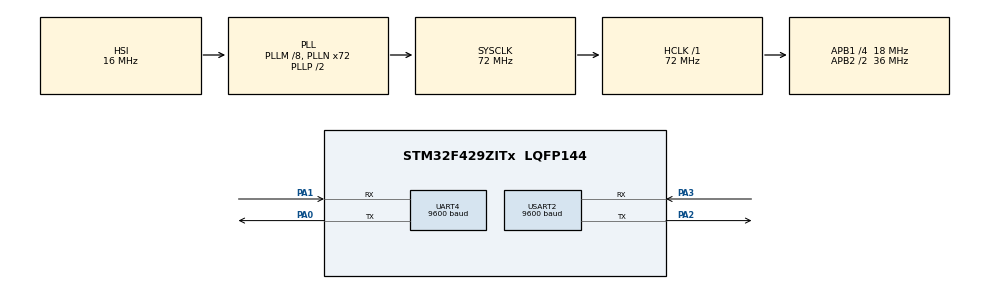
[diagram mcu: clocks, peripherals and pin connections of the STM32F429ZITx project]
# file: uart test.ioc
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Mcu.Family=STM32F4
Mcu.Name=STM32F429ZITx
Mcu.Package=LQFP144
Mcu.UserConstants=out,1
NVIC.PriorityGroup=NVIC_PRIORITYGROUP_4
NVIC.TIM1_UP_TIM10_IRQn=true\:0\:0\:false\:false\:true\:false\:true
NVIC.TimeBase=TIM1_UP_TIM10_IRQn
NVIC.TimeBaseIP=TIM1
NVIC.UART4_IRQn=true\:0\:0\:false\:false\:true\:true\:true
NVIC.USART2_IRQn=true\:0\:0\:false\:false\:true\:true\:true
PA0/WKUP.Mode=Asynchronous
PA0/WKUP.Signal=UART4_TX
PA1.Mode=Asynchronous
PA1.Signal=UART4_RX
PA2.Mode=Asynchronous
PA2.Signal=USART2_TX
PA3.Mode=Asynchronous
PA3.Signal=USART2_RX
ProjectManager.HeapSize=0x200
ProjectManager.StackSize=0x400
ProjectManager.TargetToolchain=MDK-ARM V5
RCC.48MHZClocksFreq_Value=48000000
RCC.AHBFreq_Value=72000000
RCC.APB1CLKDivider=RCC_HCLK_DIV4
RCC.APB1Freq_Value=18000000
RCC.APB1TimFreq_Value=36000000
RCC.APB2CLKDivider=RCC_HCLK_DIV2
RCC.APB2Freq_Value=36000000
RCC.APB2TimFreq_Value=72000000
RCC.CortexFreq_Value=72000000
RCC.HCLKFreq_Value=72000000
RCC.HSE_VALUE=8000000
RCC.HSI_VALUE=16000000
RCC.LSE_VALUE=32768
RCC.PLLM=8
RCC.PLLN=72
RCC.PLLQ=3
RCC.PLLSAIN=50
RCC.SYSCLKFreq_VALUE=72000000
RCC.SYSCLKSource=RCC_SYSCLKSOURCE_PLLCLK
RCC.VCOOutputFreq_Value=144000000
UART4.BaudRate=9600
UART4.VirtualMode=Asynchronous
USART2.BaudRate=9600
USART2.VirtualMode=VM_ASYNC
VP_SYS_VS_tim1.Mode=TIM1
board=STM32F429I-DISC1

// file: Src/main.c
/* USER CODE BEGIN Header */
/**
  ******************************************************************************
  * @file           : main.c
  * @brief          : Main program body
  ******************************************************************************
  * @attention
  *
  * <h2><center>&copy; Copyright (c) 2020 STMicroelectronics.
  * All rights reserved.</center></h2>
  *
  * This software component is licensed by ST under BSD 3-Clause license,
  * the "License"; You may not use this file except in compliance with the
  * License. You may obtain a copy of the License at:
  *                        opensource.org/licenses/BSD-3-Clause
  *
  ******************************************************************************
  */
/* USER CODE END Header */

#include "main.h"

UART_HandleTypeDef huart4;
UART_HandleTypeDef huart2;

volatile uint8_t input_buffer[4],read_spot=0,array_size,request_id1,request_id2;
uint8_t buffer[1],previous_id,INFORMATION,input_byte,previous_id2;
#define YES				1
#define NO				0

void SystemClock_Config(void);
static void MX_GPIO_Init(void);
static void MX_UART4_Init(void);
static void MX_USART2_UART_Init(void);

/* USER CODE BEGIN 0 */
	uint8_t data[]="pp";

	void HAL_UART_RxCpltCallback(UART_HandleTypeDef *huart)
{
	if(huart->Instance==USART2)
		{
		HAL_UART_Receive_IT(&huart2, buffer,1);
					HAL_UART_Transmit(&huart4, buffer,sizeof(buffer),10);
		input_byte= buffer[0];//move recieved byte to variable input_byte

			if(input_byte==0x26)
			{
				INFORMATION=YES;

			}

			if(INFORMATION==YES)
			{
			input_buffer[read_spot]=input_byte;
			read_spot++;
			}

			if(input_byte==0x5E)
			{
		}

}
		}

/* USER CODE END 0 */

int main(void)
{

  /* MCU Configuration--------------------------------------------------------*/

  /* Reset of all peripherals, Initializes the Flash interface and the Systick. */
  HAL_Init();

  /* Configure the system clock */
  SystemClock_Config();

  /* Initialize all configured peripherals */
  MX_GPIO_Init();
  MX_UART4_Init();
  MX_USART2_UART_Init();
  /* USER CODE BEGIN 2 */
  HAL_UART_Receive_IT(&huart2,buffer,1);
  /* USER CODE END 2 */

  /* Infinite loop */
  while (1)
  {
//	HAL_UART_Transmit(&huart4,data,sizeof (data),1000);
		//data=data+1;
//		HAL_Delay(1000);
  }
}

void SystemClock_Config(void)
{
  RCC_OscInitTypeDef RCC_OscInitStruct = {0};
  RCC_ClkInitTypeDef RCC_ClkInitStruct = {0};

  /** Configure the main internal regulator output voltage
  */
  __HAL_RCC_PWR_CLK_ENABLE();
  __HAL_PWR_VOLTAGESCALING_CONFIG(PWR_REGULATOR_VOLTAGE_SCALE3);
  /** Initializes the CPU, AHB and APB busses clocks
  */
  RCC_OscInitStruct.OscillatorType = RCC_OSCILLATORTYPE_HSI;
  RCC_OscInitStruct.HSIState = RCC_HSI_ON;
  RCC_OscInitStruct.HSICalibrationValue = RCC_HSICALIBRATION_DEFAULT;
  RCC_OscInitStruct.PLL.PLLState = RCC_PLL_ON;
  RCC_OscInitStruct.PLL.PLLSource = RCC_PLLSOURCE_HSI;
  RCC_OscInitStruct.PLL.PLLM = 8;
  RCC_OscInitStruct.PLL.PLLN = 72;
  RCC_OscInitStruct.PLL.PLLP = RCC_PLLP_DIV2;
  RCC_OscInitStruct.PLL.PLLQ = 3;
  if (HAL_RCC_OscConfig(&RCC_OscInitStruct) != HAL_OK)
  {
    Error_Handler();
  }
  /** Initializes the CPU, AHB and APB busses clocks
  */
  RCC_ClkInitStruct.ClockType = RCC_CLOCKTYPE_HCLK|RCC_CLOCKTYPE_SYSCLK
                              |RCC_CLOCKTYPE_PCLK1|RCC_CLOCKTYPE_PCLK2;
  RCC_ClkInitStruct.SYSCLKSource = RCC_SYSCLKSOURCE_PLLCLK;
  RCC_ClkInitStruct.AHBCLKDivider = RCC_SYSCLK_DIV1;
  RCC_ClkInitStruct.APB1CLKDivider = RCC_HCLK_DIV4;
  RCC_ClkInitStruct.APB2CLKDivider = RCC_HCLK_DIV2;

  if (HAL_RCC_ClockConfig(&RCC_ClkInitStruct, FLASH_LATENCY_2) != HAL_OK)
  {
    Error_Handler();
  }
}

static void MX_UART4_Init(void)
{

  huart4.Instance = UART4;
  huart4.Init.BaudRate = 9600;
  huart4.Init.WordLength = UART_WORDLENGTH_8B;
  huart4.Init.StopBits = UART_STOPBITS_1;
  huart4.Init.Parity = UART_PARITY_NONE;
  huart4.Init.Mode = UART_MODE_TX_RX;
  huart4.Init.HwFlowCtl = UART_HWCONTROL_NONE;
  huart4.Init.OverSampling = UART_OVERSAMPLING_16;
  if (HAL_UART_Init(&huart4) != HAL_OK)
  {
    Error_Handler();
  }

}

static void MX_USART2_UART_Init(void)
{

  huart2.Instance = USART2;
  huart2.Init.BaudRate = 9600;
  huart2.Init.WordLength = UART_WORDLENGTH_8B;
  huart2.Init.StopBits = UART_STOPBITS_1;
  huart2.Init.Parity = UART_PARITY_NONE;
  huart2.Init.Mode = UART_MODE_TX_RX;
  huart2.Init.HwFlowCtl = UART_HWCONTROL_NONE;
  huart2.Init.OverSampling = UART_OVERSAMPLING_16;
  if (HAL_UART_Init(&huart2) != HAL_OK)
  {
    Error_Handler();
  }

}

static void MX_GPIO_Init(void)
{

  /* GPIO Ports Clock Enable */
  __HAL_RCC_GPIOA_CLK_ENABLE();

}

 /**
  * @brief  Period elapsed callback in non blocking mode
  * @note   This function is called  when TIM1 interrupt took place, inside
  * HAL_TIM_IRQHandler(). It makes a direct call to HAL_IncTick() to increment
  * a global variable "uwTick" used as application time base.
  * @param  htim : TIM handle
  * @retval None
  */
void HAL_TIM_PeriodElapsedCallback(TIM_HandleTypeDef *htim)
{
  if (htim->Instance == TIM1) {
    HAL_IncTick();
  }
}

void Error_Handler(void)
{
}

/************************ (C) COPYRIGHT STMicroelectronics *****END OF FILE****/
